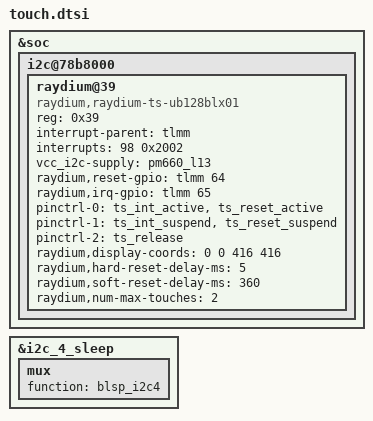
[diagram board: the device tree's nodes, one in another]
/*
 * Copyright (c) 2017-2019, The Linux Foundation. All rights reserved.
 *
 * This program is free software; you can redistribute it and/or modify
 * it under the terms of the GNU General Public License version 2 and
 * only version 2 as published by the Free Software Foundation.
 *
 * This program is distributed in the hope that it will be useful,
 * but WITHOUT ANY WARRANTY; without even the implied warranty of
 * MERCHANTABILITY or FITNESS FOR A PARTICULAR PURPOSE.  See the
 * GNU General Public License for more details.
 */
/* Pinctrl dt nodes for interrupt and reset gpio for Raydium controller */
&soc {
	i2c@78b8000 { /* BLSP1 QUP4 */
		status = "ok";
		raydium@39 {
			compatible = "raydium,raydium-ts-ub128blx01", "raydium,raydium-ts-h120blx01";
			reg = <0x39>;
			interrupt-parent = <&tlmm>;
			interrupts = <98 0x2002>;
			vcc_i2c-supply = <&pm660_l13>;
			raydium,reset-gpio = <&tlmm 64 0x00>;
			raydium,irq-gpio =<&tlmm 65 0x2002>;
			/* pins used by touchscreen */
			pinctrl-names = "pmx_ts_active","pmx_ts_suspend","pmx_ts_release";
			pinctrl-0 = <&ts_int_active &ts_reset_active>;
			pinctrl-1 = <&ts_int_suspend &ts_reset_suspend>;
			pinctrl-2 = <&ts_release>;
			raydium,display-coords = <0 0 416 416>;
			raydium,hard-reset-delay-ms = <5>;
			raydium,soft-reset-delay-ms = <360>;
			raydium,num-max-touches = <2>;
		};
	};
};

&i2c_4_sleep {
	mux {
		/* pins = "gpio14", "gpio15"; */
		function = "blsp_i2c4";
	};
};

